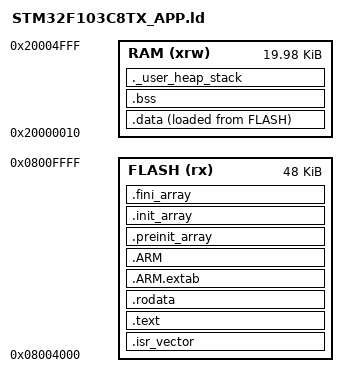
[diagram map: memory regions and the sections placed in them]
/*
******************************************************************************
**
**  File        : STM32F103C8TX_APP.ld
**
**  Author      : Auto-generated for bootloader application
**
**  Abstract    : Linker script for STM32F103C8Tx Application
**                Works with STM32F103C8T6 Bootloader
**                Application starts at 0x08004000 (after 16KB bootloader)
**                Available Flash: 48KB
**                Available RAM: 20KB
**
**  Target      : STMicroelectronics STM32F103C8T6
**
******************************************************************************
*/

/* Entry Point */
ENTRY(Reset_Handler)

/* Highest address of the user mode stack */
_estack = ORIGIN(RAM) + LENGTH(RAM); /* end of "RAM" Ram type memory */

_Min_Heap_Size = 0x200;  /* required amount of heap  */
_Min_Stack_Size = 0x400; /* required amount of stack */

/* Memories definition */
MEMORY
{
  FLASH (rx)      : ORIGIN = 0x08004000, LENGTH = 48K    /* Application Flash area */
  RAM (xrw)       : ORIGIN = 0x20000010, LENGTH = 20K - 0x10   /* SRAM */
}

/* Define bootloader area for reference (not used by application) */
__bootloader_start__ = 0x08000000;
__bootloader_size__ = 0x4000;  /* 16KB */
__app_start__ = 0x08004000;

/* Sections */
SECTIONS
{
  /* The startup code goes first into FLASH */
  .isr_vector :
  {
    . = ALIGN(4);
    KEEP(*(.isr_vector)) /* Startup code */
    . = ALIGN(4);
  } >FLASH

  /* The program code and other data goes into FLASH */
  .text :
  {
    . = ALIGN(4);
    *(.text)           /* .text sections (code) */
    *(.text*)          /* .text* sections (code) */
    *(.glue_7)         /* glue arm to thumb code */
    *(.glue_7t)        /* glue thumb to arm code */
    *(.eh_frame)

    KEEP (*(.init))
    KEEP (*(.fini))

    . = ALIGN(4);
    _etext = .;        /* define a global symbols at end of code */
  } >FLASH

  /* Constant data goes into FLASH */
  .rodata :
  {
    . = ALIGN(4);
    *(.rodata)         /* .rodata sections (constants, strings, etc.) */
    *(.rodata*)        /* .rodata* sections (constants, strings, etc.) */
    . = ALIGN(4);
  } >FLASH

  .ARM.extab   : {
    . = ALIGN(4);
    *(.ARM.extab* .gnu.linkonce.armextab.*)
    . = ALIGN(4);
  } >FLASH

  .ARM : {
    . = ALIGN(4);
    __exidx_start = .;
    *(.ARM.exidx*)
    __exidx_end = .;
    . = ALIGN(4);
  } >FLASH

  .preinit_array     :
  {
    . = ALIGN(4);
    PROVIDE_HIDDEN (__preinit_array_start = .);
    KEEP (*(.preinit_array*))
    PROVIDE_HIDDEN (__preinit_array_end = .);
    . = ALIGN(4);
  } >FLASH

  .init_array :
  {
    . = ALIGN(4);
    PROVIDE_HIDDEN (__init_array_start = .);
    KEEP (*(SORT(.init_array.*)))
    KEEP (*(.init_array*))
    PROVIDE_HIDDEN (__init_array_end = .);
    . = ALIGN(4);
  } >FLASH

  .fini_array :
  {
    . = ALIGN(4);
    PROVIDE_HIDDEN (__fini_array_start = .);
    KEEP (*(SORT(.fini_array.*)))
    KEEP (*(.fini_array*))
    PROVIDE_HIDDEN (__fini_array_end = .);
    . = ALIGN(4);
  } >FLASH

  /* used by the startup to initialize data */
  _sidata = LOADADDR(.data);

  /* Initialized data sections goes into RAM, load LMA copy after code */
  .data :
  {
    . = ALIGN(4);
    _sdata = .;        /* create a global symbol at data start */
    *(.data)           /* .data sections */
    *(.data*)          /* .data* sections */
    *(.RamFunc)        /* .RamFunc sections */
    *(.RamFunc*)       /* .RamFunc* sections */

    . = ALIGN(4);
    _edata = .;        /* define a global symbol at data end */

  } >RAM AT> FLASH


  /* Uninitialized data section */
  . = ALIGN(4);
  .bss :
  {
    /* This is used by the startup in order to initialize the .bss section */
    _sbss = .;         /* define a global symbol at bss start */
    __bss_start__ = _sbss;
    *(.bss)
    *(.bss*)
    *(COMMON)

    . = ALIGN(4);
    _ebss = .;         /* define a global symbol at bss end */
    __bss_end__ = _ebss;
  } >RAM

  /* User_heap_stack section, used to check that there is enough RAM left */
  ._user_heap_stack :
  {
    . = ALIGN(8);
    PROVIDE ( end = . );
    PROVIDE ( _end = . );
    . = . + _Min_Heap_Size;
    . = . + _Min_Stack_Size;
    . = ALIGN(8);
  } >RAM

  /* Remove information from the standard libraries */
  /DISCARD/ :
  {
    libc.a ( * )
    libm.a ( * )
    libgcc.a ( * )
  }

  .ARM.attributes 0 : { *(.ARM.attributes) }

  /* Application size calculation */
  __app_size__ = _etext - __app_start__;

  /* Ensure application doesn't exceed available space */
  ASSERT(__app_size__ <= 49152, "Application size exceeds available Flash space (48KB)")

  /* Ensure we don't overflow into bootloader area */
  ASSERT(_etext <= 0x08010000, "Application overflows into reserved area")
}
